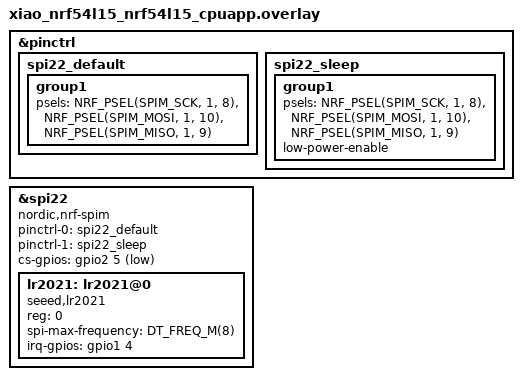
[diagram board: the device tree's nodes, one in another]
/*
 * Meshtastic nRF54L15 — DTS overlay for XIAO nRF54L15 + LR2021
 *
 * Phase 2: Map LR2021 radio to SPI22 to match Renode platform (xiao_nrf54l15.repl).
 * The Renode model connects lr2021 to spim22 @ 0x500C8000 with CS at gpio2.5.
 *
 * Note: The semtech_wio_lr2021 shield uses xiao_spi/spi00 — not compatible with
 * the Renode platform. We configure spi22 directly here instead.
 */

#include <zephyr/dt-bindings/gpio/gpio.h>

&pinctrl {
	spi22_default: spi22_default {
		group1 {
			psels = <NRF_PSEL(SPIM_SCK,  1, 8)>,
				<NRF_PSEL(SPIM_MOSI, 1, 10)>,
				<NRF_PSEL(SPIM_MISO, 1, 9)>;
		};
	};

	spi22_sleep: spi22_sleep {
		group1 {
			psels = <NRF_PSEL(SPIM_SCK,  1, 8)>,
				<NRF_PSEL(SPIM_MOSI, 1, 10)>,
				<NRF_PSEL(SPIM_MISO, 1, 9)>;
			low-power-enable;
		};
	};
};

&spi22 {
	compatible = "nordic,nrf-spim";
	status = "okay";
	pinctrl-0 = <&spi22_default>;
	pinctrl-1 = <&spi22_sleep>;
	pinctrl-names = "default", "sleep";
	cs-gpios = <&gpio2 5 GPIO_ACTIVE_LOW>;

	lr2021: lr2021@0 {
		compatible = "seeed,lr2021";
		reg = <0>;
		spi-max-frequency = <DT_FREQ_M(8)>;
		irq-gpios = <&gpio1 4 GPIO_ACTIVE_HIGH>;
	};
};
